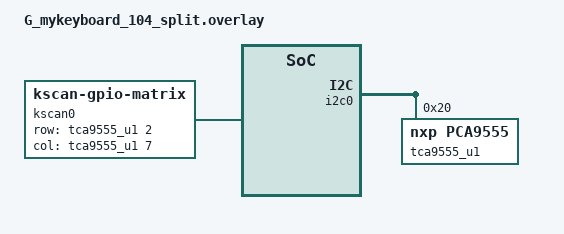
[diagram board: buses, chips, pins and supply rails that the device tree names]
#include <dt-bindings/zmk/matrix_transform.h>
#include <zephyr/dt-bindings/gpio/gpio.h>

/ {
    chosen {
        zmk,kscan = &kscan0;
        zmk,matrix-transform = &default_transform;
    };

    kscan0: kscan {
        compatible = "zmk,kscan-gpio-matrix";
        diode-direction = "col2row";

        row-gpios = <&tca9555_u1 2 GPIO_ACTIVE_HIGH>;
        col-gpios = <&tca9555_u1 7 GPIO_ACTIVE_HIGH>;
    };

    default_transform: matrix_transform {
        compatible = "zmk,matrix-transform";
        rows = <1>;
        columns = <1>;

        map = <
            RC(0,0)
        >;
    };
};

&i2c0 {
    status = "okay";

    tca9555_u1: tca9555@20 {
        compatible = "nxp,pca9555", "nxp,pca95xx";
        reg = <0x20>;

        gpio-controller;
        #gpio-cells = <2>;
        ngpios = <16>;

        status = "okay";
    };
};
